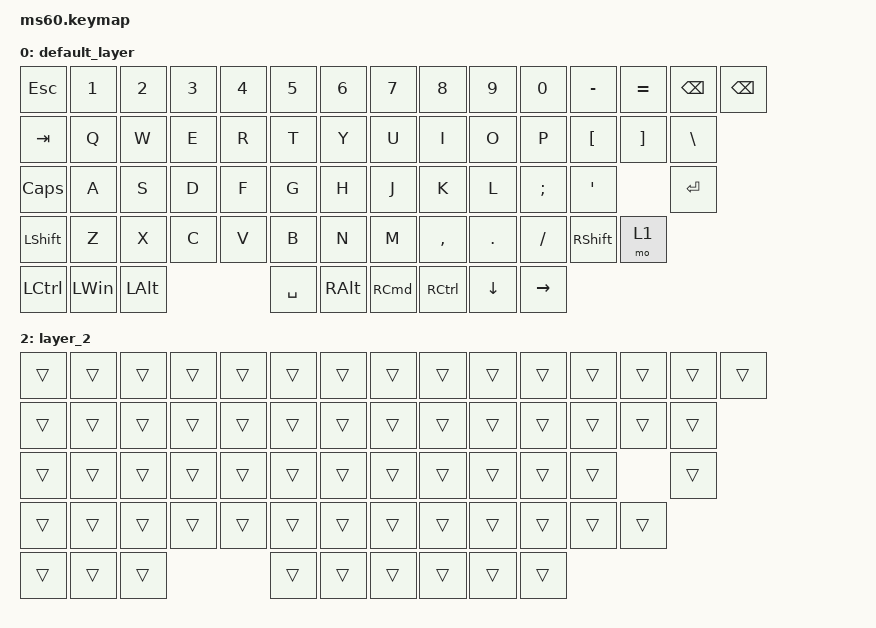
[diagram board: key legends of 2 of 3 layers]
#include <behaviors.dtsi>
#include <dt-bindings/zmk/bt.h>
#include <dt-bindings/zmk/keys.h>
#include <dt-bindings/zmk/outputs.h>
#include <dt-bindings/zmk/rgb.h>

/ {
    keymap {
        compatible = "zmk,keymap";

        default_layer {
            // -------------------------------------------------------------------------------------------
            // | ESC |  1  |  2  |  3  |  4  |  5  |  6  |  7  |  8  |  9  |  0  |  -  |  =  | BKSP |BKSP|
            // | TAB  |  Q  |  W  |  E  |  R  |  T  |  Y  |  U  |  I  |  O  |  P  |  [  |  ]  |   "|"    |
            // | CAPS  |  A  |  S  |  D  |  F  |  G  |  H  |  J  |  K  |  L  |  ;  |  '  |     ENTER     |
            // |  SHIFT  |  Z  |  X  |  C  |  V  |  B  |  N  |  M  |  ,  |  .  |   SHFT   |  UP  |   /   |
            // |  CTL  |  WIN  |  ALT  |           SPACE             | FN(1) | WIN | LEFT | DOWN | RIGHT |
            // -------------------------------------------------------------------------------------------

            bindings = <
  &kp ESCAPE        &kp N1    &kp N2  &kp N3  &kp N4     &kp N5         &kp N6    &kp N7             &kp N8    &kp N9     &kp N0        &kp MINUS  &kp EQUAL  &kp BSPC  &kp BSPC
     &kp TAB         &kp Q     &kp W   &kp E   &kp R      &kp T          &kp Y     &kp U              &kp I     &kp O      &kp P         &kp LBKT   &kp RBKT  &kp BSLH
&kp CAPSLOCK         &kp A     &kp S   &kp D   &kp F      &kp G          &kp H     &kp J              &kp K     &kp L   &kp SEMI          &kp SQT              &kp RET
   &kp LSHFT         &kp Z     &kp X   &kp C   &kp V      &kp B          &kp N     &kp M          &kp COMMA   &kp DOT  &kp SLASH  &kp RIGHT_SHIFT      &mo 1
   &kp LCTRL  &kp LEFT_WIN  &kp LALT                  &kp SPACE  &kp RIGHT_ALT  &kp RCMD  &kp RIGHT_CONTROL  &kp DOWN  &kp RIGHT
            >;
        };

        rgb_layer {
            // ------------------------------------------------------------------------------------------------
            // | BT CLR | F1  | F2  | F3  | F4  | F5  | F6  | F7  | F8  | F9  | F10 | F11 | F12 | BOOT | BOOT |
            // |  BT 1   | TOG  |  UP |   | HUEUP | SATUP | BRIUP | SPDUP |   |     |   |    |    |  RGB_efect|
            // |   BT 2   | LT |  DN  | RT | HUEDN | SATDN | BRIDN | SPDDN |   |     |   |     |  EFFECT FORW |
            // |    BT 3     |     |      |      |     |     |     |     |     |     |     |                  |
            // |   BT 4  |      |      |             TOG RGB                | PRT SCR |    |    |     |  DEL  |
            // ------------------------------------------------------------------------------------------------

            bindings = <
  &bt BT_CLR        &kp F1           &kp F2        &kp F3           &kp F4           &kp F5           &kp F6           &kp F7  &kp F8  &kp F9  &kp F10       &kp F11       &kp F12      &bootloader  &bootloader
&bt BT_SEL 0        &trans           &kp UP        &trans  &rgb_ug RGB_HUI  &rgb_ug RGB_SAI  &rgb_ug RGB_BRI  &rgb_ug RGB_SPI  &trans  &trans   &trans  &out OUT_USB  &out OUT_BLE  &rgb_ug RGB_EFR
      &trans      &kp LEFT         &kp DOWN     &kp RIGHT  &rgb_ug RGB_HUD  &rgb_ug RGB_SAD  &rgb_ug RGB_BRD  &rgb_ug RGB_SPD  &trans  &trans   &trans        &trans                &rgb_ug RGB_EFF
      &trans  &bt BT_SEL 1     &bt BT_SEL 2  &bt BT_SEL 3     &bt BT_SEL 4       &bt BT_NXT       &bt BT_PRV           &trans  &trans  &trans   &trans        &trans        &trans
      &trans        &trans  &rgb_ug RGB_TOG                                       &kp PSCRN           &trans           &trans  &trans  &trans
            >;
        };

        layer_2 {
            bindings = <
&trans  &trans  &trans  &trans  &trans  &trans  &trans  &trans  &trans  &trans  &trans  &trans  &trans  &trans  &trans
&trans  &trans  &trans  &trans  &trans  &trans  &trans  &trans  &trans  &trans  &trans  &trans  &trans  &trans
&trans  &trans  &trans  &trans  &trans  &trans  &trans  &trans  &trans  &trans  &trans  &trans          &trans
&trans  &trans  &trans  &trans  &trans  &trans  &trans  &trans  &trans  &trans  &trans  &trans  &trans
&trans  &trans  &trans                  &trans  &trans  &trans  &trans  &trans  &trans
            >;
        };
    };
};
